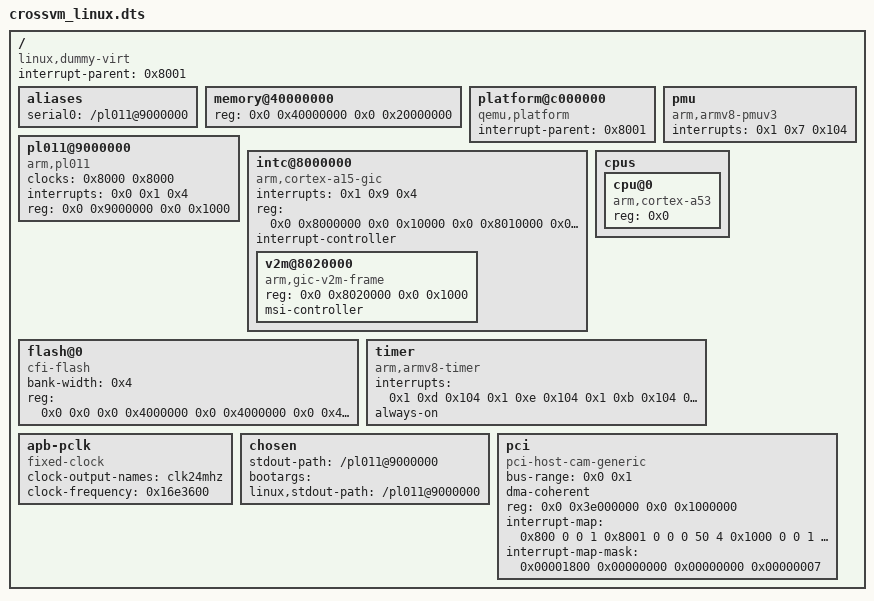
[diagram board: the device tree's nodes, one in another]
/*
 * The code contained herein is licensed under the GNU General Public
 * License. You may obtain a copy of the GNU General Public License
 * Version 2 or later at the following locations:
 *
 * http://www.opensource.org/licenses/gpl-license.html
 * http://www.gnu.org/copyleft/gpl.html
 *
 * @TAG(OTHER_GPL)
 */

/dts-v1/;

/ {
	interrupt-parent = <0x8001>;
	#size-cells = <0x2>;
	#address-cells = <0x2>;
	compatible = "linux,dummy-virt";

    aliases {
		serial0 = "/pl011@9000000";
    };

	memory@40000000 {
		reg = <0x0 0x40000000 0x0 0x20000000>;
		device_type = "memory";
	};

	platform@c000000 {
		interrupt-parent = <0x8001>;
		ranges = <0x0 0x0 0xc000000 0x2000000>;
		#address-cells = <0x1>;
		#size-cells = <0x1>;
		compatible = "qemu,platform", "simple-bus";
	};

	pl011@9000000 {
		clock-names = "uartclk", "apb_pclk";
		clocks = <0x8000 0x8000>;
		interrupts = <0x0 0x1 0x4>;
		reg = <0x0 0x9000000 0x0 0x1000>;
		compatible = "arm,pl011", "arm,primecell";
	};

	pmu {
		interrupts = <0x1 0x7 0x104>;
		compatible = "arm,armv8-pmuv3";
	};

	intc@8000000 {
		phandle = <0x8001>;
		interrupts = <0x1 0x9 0x4>;
		reg = <0x0 0x8000000 0x0 0x10000 0x0 0x8010000 0x0 0x10000 0x0 0x8030000 0x0 0x10000 0x0 0x8040000 0x0 0x10000>;
		compatible = "arm,cortex-a15-gic";
		ranges;
		#size-cells = <0x2>;
		#address-cells = <0x2>;
		interrupt-controller;
		#interrupt-cells = <0x3>;

		v2m@8020000 {
			phandle = <0x8002>;
			reg = <0x0 0x8020000 0x0 0x1000>;
			msi-controller;
			compatible = "arm,gic-v2m-frame";
		};
	};

	flash@0 {
		bank-width = <0x4>;
		reg = <0x0 0x0 0x0 0x4000000 0x0 0x4000000 0x0 0x4000000>;
		compatible = "cfi-flash";
	};

	cpus {
		#size-cells = <0x0>;
		#address-cells = <0x1>;

		cpu@0 {
			reg = <0x0>;
			compatible = "arm,cortex-a53";
			device_type = "cpu";
		};
	};

	timer {
		interrupts = <0x1 0xd 0x104 0x1 0xe 0x104 0x1 0xb 0x104 0x1 0xa 0x104>;
		always-on;
		compatible = "arm,armv8-timer", "arm,armv7-timer";
	};

	apb-pclk {
		phandle = <0x8000>;
		clock-output-names = "clk24mhz";
		clock-frequency = <0x16e3600>;
		#clock-cells = <0x0>;
		compatible = "fixed-clock";
	};

	chosen {
		stdout-path = "/pl011@9000000";
		bootargs = "";
		linux,stdout-path = "/pl011@9000000";
    };

    /* seL4 Virtual PCI device */
    pci {
        compatible = "pci-host-cam-generic";
        device_type = "pci";
        #address-cells = <0x3>;
        #size-cells =  <0x2>;
        bus-range = <0x0 0x1>;
        dma-coherent;
        #interrupt-cells = <0x1>;

        reg = <0x0 0x3e000000 0x0 0x1000000>;
        ranges = <0x01000000 0x0 0x00000000 0x0 0x3d000000 0x0 0x00010000>,
                 <0x02000000 0x0 0x3f000000 0x0 0x3f000000 0x0 0x1000000>;

        interrupt-map = <0x800  0 0 1 0x8001 0 0 0 50  4
						 0x1000 0 0 1 0x8001 0 0 0 50  4
						 0x1800 0 0 1 0x8001 0 0 0 50  4
						 0x2000 0 0 1 0x8001 0 0 0 50  4
                         0x2800 0 0 1 0x8001 0 0 0 50  4>;

        interrupt-map-mask = <0x00001800 0x00000000 0x00000000 0x00000007>;
    };
};
